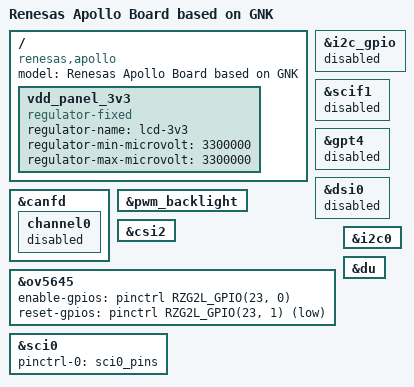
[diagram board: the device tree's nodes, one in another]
// SPDX-License-Identifier: (GPL-2.0-only OR BSD-2-Clause)
/*
 * Device Tree Source for the RZ/G2L Apollo board
 *
 * Copyright (C) 2024 Regulus Corp.
 */

/dts-v1/;
#include "r9a07g044l2.dtsi"
#include "rzg2l-smarc-som.dtsi"
#include "rzg2l-apollo-pinfunction.dtsi"
#include "rz-gnk-smarc-common.dtsi"

/ {
	model = "Renesas Apollo Board based on GNK";
	compatible = "renesas,apollo", "renesas,r9a07g044l2", "renesas,r9a07g044";

	vdd_panel_3v3: vdd_panel_3v3 {
		compatible = "regulator-fixed";
		regulator-name = "lcd-3v3";
		regulator-min-microvolt = <3300000>;
		regulator-max-microvolt = <3300000>;
	};
};

&i2c_gpio {
	status = "disabled";
};

&canfd {
	channel0 {
		status = "disabled";
	};
};

&scif1 {
	status = "disabled";
};

&gpt4 {
	status = "disabled";
};

&pwm_backlight {
	status = "okay";
};

&dsi0 {
	status = "disabled";
};

&csi2 {
	status = "okay";
};

&ov5645 {
	status = "okay";
	enable-gpios = <&pinctrl RZG2L_GPIO(23, 0) GPIO_ACTIVE_HIGH>;
	reset-gpios = <&pinctrl RZG2L_GPIO(23, 1) GPIO_ACTIVE_LOW>;
};

&i2c0 {
	status = "okay";
};

&du {
	status = "okay";
};

&sci0 {
	pinctrl-0 = <&sci0_pins>;
	pinctrl-names = "default";
	status = "okay";
};
